# TESTDEV register map
Registers are 32-bit, access not given, no defined reset value unless marked. A register's access mark holds for its fields unless they carry their own. Offsets are from the block's base; lines under a group give offsets from that group; [hi:lo] are bit positions; {n}, {i} and the like mark numbered series; 'fields as' and 'values as' point back to an identical list; <NAME> marks a mode.

## Memory map
0x40010000 GPIOA — General-purpose I/O
0x40011000 GPIOB
0x40020000 TIMER — A timer whose name is a Jai keyword: if

## Interrupts
7 GPIOA
8 GPIOB

## GPIOA — General-purpose I/O
Base 0x40010000
Same registers: GPIOB 0x40011000
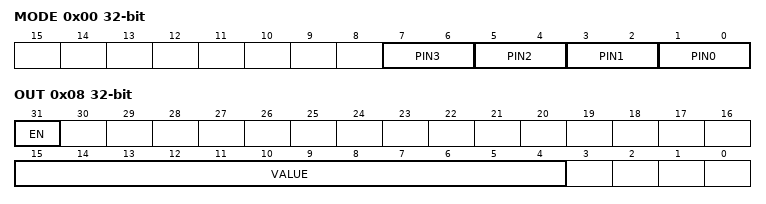
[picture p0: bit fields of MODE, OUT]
0x00 MODE
  [2n+1:2n] PIN{n} (n=0..3)
    0=INPUT; 1=OUTPUT; 0b1x=ANY
0x08 OUT
  [31] EN, [15:4] VALUE
0x0C CTRL_A — Control (mode A)
0x0C CTRL_B (alternate view of CTRL_A) — Control (mode B)
0x0E CTRL_HI 16-bit — Upper half of CTRL in mode B
  [15:8] X
{0x20+4i} PCR[{i}] (i=0..7)
  [10:8] MUX
0x40 FILT_{x} (x=LO,HI; step 0x8) 16-bit
{0x100+0x10*i} CH[{i}] (i=0..2) group
  0x00 CFG
    [0] ON
  0x08 DATA

## TIMER — A timer whose name is a Jai keyword: if
Base 0x40020000
0x00 if
0x08 COUNT 64-bit
